AUTOSAR XML (schema 4-2-2)
package /EB/SoftwareComponents
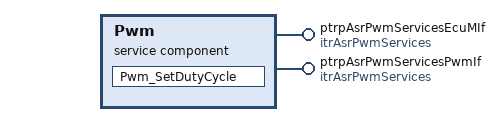
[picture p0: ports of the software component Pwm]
  service sw component type Pwm: category=ASR_Interfaces
    provide port ptrpAsrPwmServicesEcuMIf: provided-interface=itrAsrPwmServices
    provide port ptrpAsrPwmServicesPwmIf: provided-interface=itrAsrPwmServices
    behavior Pwm_IB: handle-termination-and-restart=NO-SUPPORT
      runnable Pwm_SetDutyCycle: external-triggering-point=ptrpAsrPwmServicesPwmIf.Pwm_SetDutyCycle
package /EB/TriggerInterfaces
  trigger interface itrAsrPwmServices
    trigger Pwm_Init: trigger-period={cse-code=1000, cse-code-factor=0}
    trigger Pwm_SetDutyCycle: trigger-period={cse-code=1000, cse-code-factor=0}
